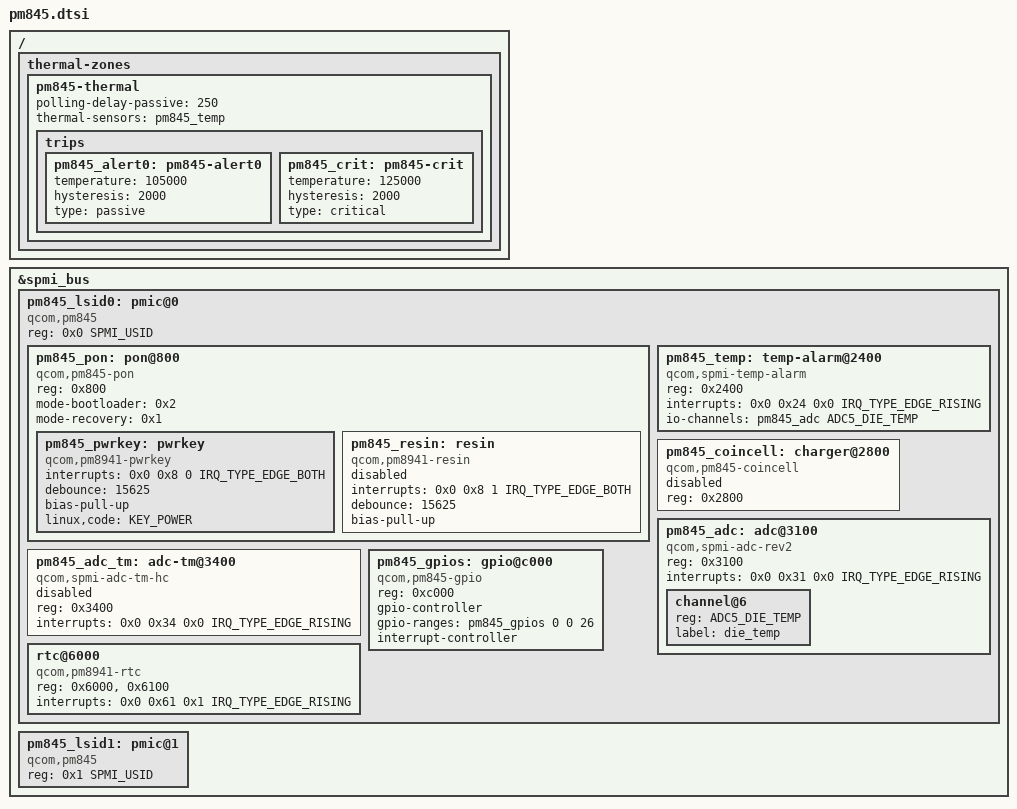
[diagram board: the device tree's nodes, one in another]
// SPDX-License-Identifier: (GPL-2.0+ OR MIT)
/* Copyright 2018 Google LLC. */

#include <dt-bindings/iio/qcom,spmi-vadc.h>
#include <dt-bindings/input/linux-event-codes.h>
#include <dt-bindings/interrupt-controller/irq.h>
#include <dt-bindings/spmi/spmi.h>
#include <dt-bindings/thermal/thermal.h>

/ {
	thermal-zones {
		pm845-thermal {
			polling-delay-passive = <250>;

			thermal-sensors = <&pm845_temp>;

			trips {
				pm845_alert0: pm845-alert0 {
					temperature = <105000>;
					hysteresis = <2000>;
					type = "passive";
				};
				pm845_crit: pm845-crit {
					temperature = <125000>;
					hysteresis = <2000>;
					type = "critical";
				};
			};
		};
	};
};

&spmi_bus {
	pm845_lsid0: pmic@0 {
		compatible = "qcom,pm845", "qcom,spmi-pmic";
		reg = <0x0 SPMI_USID>;
		#address-cells = <1>;
		#size-cells = <0>;

		pm845_pon: pon@800 {
			compatible = "qcom,pm845-pon";

			reg = <0x800>;
			mode-bootloader = <0x2>;
			mode-recovery = <0x1>;

			pm845_pwrkey: pwrkey {
				compatible = "qcom,pm8941-pwrkey";
				interrupts = <0x0 0x8 0 IRQ_TYPE_EDGE_BOTH>;
				debounce = <15625>;
				bias-pull-up;
				linux,code = <KEY_POWER>;
			};

			pm845_resin: resin {
				compatible = "qcom,pm8941-resin";
				interrupts = <0x0 0x8 1 IRQ_TYPE_EDGE_BOTH>;
				debounce = <15625>;
				bias-pull-up;
				status = "disabled";
			};
		};

		pm845_temp: temp-alarm@2400 {
			compatible = "qcom,spmi-temp-alarm";
			reg = <0x2400>;
			interrupts = <0x0 0x24 0x0 IRQ_TYPE_EDGE_RISING>;
			io-channels = <&pm845_adc ADC5_DIE_TEMP>;
			io-channel-names = "thermal";
			#thermal-sensor-cells = <0>;
		};

		pm845_coincell: charger@2800 {
			compatible = "qcom,pm845-coincell", "qcom,pm8941-coincell";
			reg = <0x2800>;

			status = "disabled";
		};

		pm845_adc: adc@3100 {
			compatible = "qcom,spmi-adc-rev2";
			reg = <0x3100>;
			interrupts = <0x0 0x31 0x0 IRQ_TYPE_EDGE_RISING>;
			#address-cells = <1>;
			#size-cells = <0>;
			#io-channel-cells = <1>;

			channel@6 {
				reg = <ADC5_DIE_TEMP>;
				label = "die_temp";
			};
		};

		pm845_adc_tm: adc-tm@3400 {
			compatible = "qcom,spmi-adc-tm-hc";
			reg = <0x3400>;
			interrupts = <0x0 0x34 0x0 IRQ_TYPE_EDGE_RISING>;
			#thermal-sensor-cells = <1>;
			#address-cells = <1>;
			#size-cells = <0>;
			status = "disabled";
		};

		rtc@6000 {
			compatible = "qcom,pm8941-rtc";
			reg = <0x6000>, <0x6100>;
			reg-names = "rtc", "alarm";
			interrupts = <0x0 0x61 0x1 IRQ_TYPE_EDGE_RISING>;
		};

		pm845_gpios: gpio@c000 {
			compatible = "qcom,pm845-gpio", "qcom,spmi-gpio";
			reg = <0xc000>;
			gpio-controller;
			gpio-ranges = <&pm845_gpios 0 0 26>;
			#gpio-cells = <2>;
			interrupt-controller;
			#interrupt-cells = <2>;
		};

	};

	pm845_lsid1: pmic@1 {
		compatible = "qcom,pm845", "qcom,spmi-pmic";
		reg = <0x1 SPMI_USID>;
		#address-cells = <1>;
		#size-cells = <0>;
	};
};
